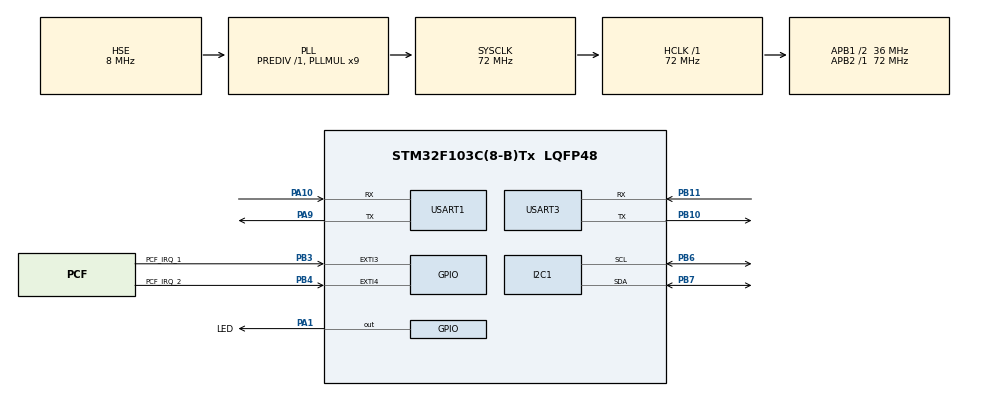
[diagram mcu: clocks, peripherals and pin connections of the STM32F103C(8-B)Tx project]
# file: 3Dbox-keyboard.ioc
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Mcu.Family=STM32F1
Mcu.Name=STM32F103C(8-B)Tx
Mcu.Package=LQFP48
NVIC.EXTI3_IRQn=true\:0\:0\:false\:false\:true\:true\:true\:true
NVIC.EXTI4_IRQn=true\:0\:0\:false\:false\:true\:true\:true\:true
NVIC.PriorityGroup=NVIC_PRIORITYGROUP_4
PA1.GPIO_Label=LED
PA1.GPIO_ModeDefaultOutputPP=GPIO_MODE_OUTPUT_OD
PA1.Signal=GPIO_Output
PA10.Mode=Asynchronous
PA10.Signal=USART1_RX
PA13.Mode=Serial_Wire
PA13.Signal=SYS_JTMS-SWDIO
PA14.Mode=Serial_Wire
PA14.Signal=SYS_JTCK-SWCLK
PA9.Mode=Asynchronous
PA9.Signal=USART1_TX
PB10.Mode=Asynchronous
PB10.Signal=USART3_TX
PB11.Mode=Asynchronous
PB11.Signal=USART3_RX
PB3.GPIO_Label=PCF_IRQ_1
PB3.GPIO_ModeDefaultEXTI=GPIO_MODE_IT_FALLING
PB3.GPIO_PuPd=GPIO_PULLUP
PB3.Signal=GPXTI3
PB4.GPIO_Label=PCF_IRQ_2
PB4.GPIO_ModeDefaultEXTI=GPIO_MODE_IT_FALLING
PB4.GPIO_PuPd=GPIO_PULLUP
PB4.Signal=GPXTI4
PB6.GPIO_Pu=GPIO_PULLUP
PB6.Mode=I2C
PB6.Signal=I2C1_SCL
PB7.GPIO_Pu=GPIO_PULLUP
PB7.Mode=I2C
PB7.Signal=I2C1_SDA
PD0-OSC_IN.Mode=HSE-External-Oscillator
PD0-OSC_IN.Signal=RCC_OSC_IN
PD1-OSC_OUT.Mode=HSE-External-Oscillator
PD1-OSC_OUT.Signal=RCC_OSC_OUT
ProjectManager.HeapSize=0x200
ProjectManager.StackSize=0x400
ProjectManager.TargetToolchain=STM32CubeIDE
RCC.AHBFreq_Value=72000000
RCC.APB1CLKDivider=RCC_HCLK_DIV2
RCC.APB1Freq_Value=36000000
RCC.APB1TimFreq_Value=72000000
RCC.APB2Freq_Value=72000000
RCC.APB2TimFreq_Value=72000000
RCC.HCLKFreq_Value=72000000
RCC.PLLMUL=RCC_PLL_MUL9
RCC.PLLSourceVirtual=RCC_PLLSOURCE_HSE
RCC.SYSCLKFreq_VALUE=72000000
RCC.SYSCLKSource=RCC_SYSCLKSOURCE_PLLCLK
RCC.USBFreq_Value=72000000
USART1.VirtualMode=VM_ASYNC
USART3.VirtualMode=VM_ASYNC
board=custom

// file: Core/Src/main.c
/* USER CODE BEGIN Header */
/**
  ******************************************************************************
  * @file           : main.c
  * @brief          : Main program body
  ******************************************************************************
  * @attention
  *
  * <h2><center>&copy; Copyright (c) 2021 STMicroelectronics.
  * All rights reserved.</center></h2>
  *
  * This software component is licensed by ST under BSD 3-Clause license,
  * the "License"; You may not use this file except in compliance with the
  * License. You may obtain a copy of the License at:
  *                        opensource.org/licenses/BSD-3-Clause
  *
  ******************************************************************************
  */
/* USER CODE END Header */
#include "main.h"
#include "i2c.h"
#include "usart.h"
#include "gpio.h"

/* USER CODE BEGIN Includes */

	#include "VRbox-keyboards-sm.h"
	#include "kb_4x4xN_pcf8574_sm.h"

/* USER CODE END Includes */

void SystemClock_Config(void);

int main(void)
{

  /* MCU Configuration--------------------------------------------------------*/

  /* Reset of all peripherals, Initializes the Flash interface and the Systick. */
  HAL_Init();

  /* Configure the system clock */
  SystemClock_Config();

  /* Initialize all configured peripherals */
  MX_GPIO_Init();
  MX_I2C1_Init();
  MX_USART1_UART_Init();
  MX_USART3_UART_Init();
  /* USER CODE BEGIN 2 */

	PCF8574_Struct  	hpcf[ VR_KeyBoard_QNT ] ;

	PCF8574_struct_init( &hpcf[ VR_KeyBoard_0 ] , &hi2c1 ,  VR_KeyBoard_0 ,  I2C_ADR_PCF_0 ) ;
	PCF8574_struct_init( &hpcf[ VR_KeyBoard_1 ] , &hi2c1 ,  VR_KeyBoard_1 ,  I2C_ADR_PCF_1 ) ;
	PCF8574_IRQ_enable ( &hpcf[ VR_KeyBoard_0 ] ) ;
	PCF8574_IRQ_enable ( &hpcf[ VR_KeyBoard_1 ] ) ;

	VRbox_Struct 	hvrbox ;
	VRbox_Init( &hvrbox , &huart1 , &huart3 , &hi2c1 ) ;

  /* USER CODE END 2 */

  /* Infinite loop */
  /* USER CODE BEGIN WHILE */
  while (1)
  {
	VRbox_Check( &hvrbox , &hpcf[ VR_KeyBoard_0 ] ) ;
	VRbox_Check( &hvrbox , &hpcf[ VR_KeyBoard_1 ] ) ;

    /* USER CODE END WHILE */

  }
}

void SystemClock_Config(void)
{
  RCC_OscInitTypeDef RCC_OscInitStruct = {0};
  RCC_ClkInitTypeDef RCC_ClkInitStruct = {0};

  /** Initializes the RCC Oscillators according to the specified parameters
  * in the RCC_OscInitTypeDef structure.
  */
  RCC_OscInitStruct.OscillatorType = RCC_OSCILLATORTYPE_HSE;
  RCC_OscInitStruct.HSEState = RCC_HSE_ON;
  RCC_OscInitStruct.HSEPredivValue = RCC_HSE_PREDIV_DIV1;
  RCC_OscInitStruct.HSIState = RCC_HSI_ON;
  RCC_OscInitStruct.PLL.PLLState = RCC_PLL_ON;
  RCC_OscInitStruct.PLL.PLLSource = RCC_PLLSOURCE_HSE;
  RCC_OscInitStruct.PLL.PLLMUL = RCC_PLL_MUL9;
  if (HAL_RCC_OscConfig(&RCC_OscInitStruct) != HAL_OK)
  {
    Error_Handler();
  }

  /** Initializes the CPU, AHB and APB buses clocks
  */
  RCC_ClkInitStruct.ClockType = RCC_CLOCKTYPE_HCLK|RCC_CLOCKTYPE_SYSCLK
                              |RCC_CLOCKTYPE_PCLK1|RCC_CLOCKTYPE_PCLK2;
  RCC_ClkInitStruct.SYSCLKSource = RCC_SYSCLKSOURCE_PLLCLK;
  RCC_ClkInitStruct.AHBCLKDivider = RCC_SYSCLK_DIV1;
  RCC_ClkInitStruct.APB1CLKDivider = RCC_HCLK_DIV2;
  RCC_ClkInitStruct.APB2CLKDivider = RCC_HCLK_DIV1;

  if (HAL_RCC_ClockConfig(&RCC_ClkInitStruct, FLASH_LATENCY_2) != HAL_OK)
  {
    Error_Handler();
  }
}

void Error_Handler(void)
{
  __disable_irq();
  while (1)
  {
  }
}
